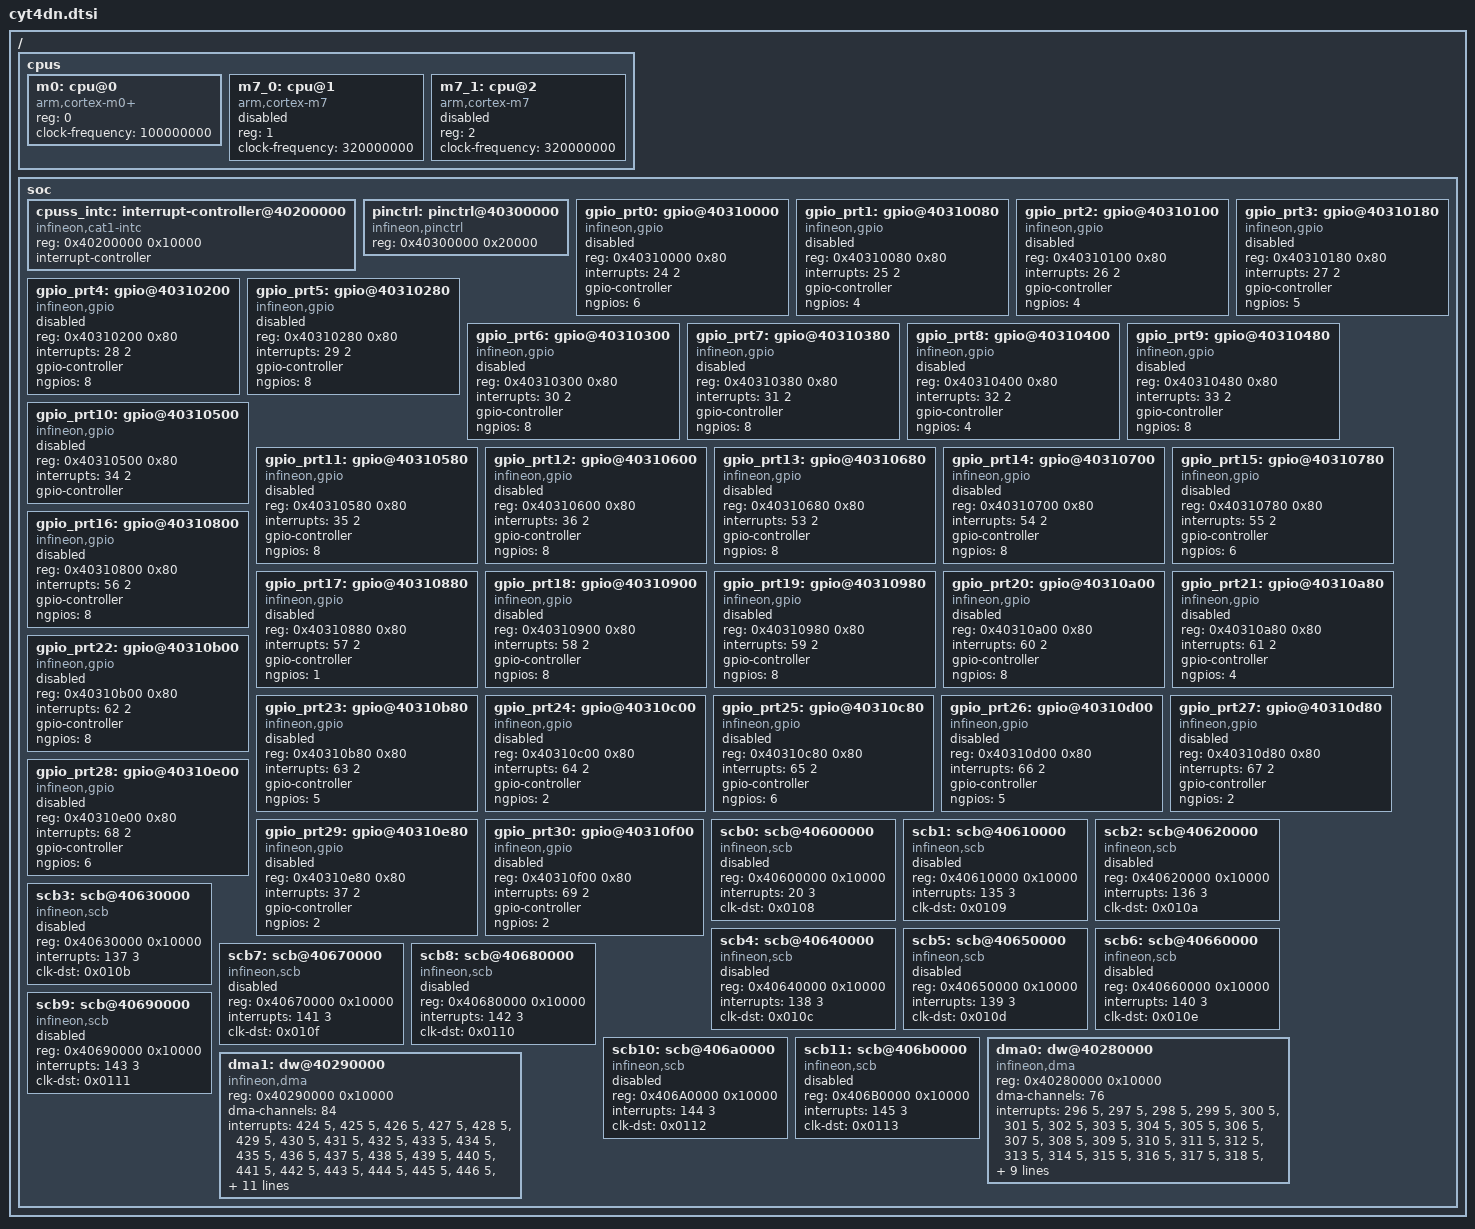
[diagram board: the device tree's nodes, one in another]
/*
 * Copyright (c) 2026 Linumiz
 * Copyright (c) 2026 Infineon Technologies AG
 *
 * SPDX-License-Identifier: Apache-2.0
 */

#include <mem.h>
#include <zephyr/dt-bindings/pinctrl/ifx_cat1-pinctrl.h>
#include <zephyr/dt-bindings/memory-attr/memory-attr-arm.h>

/ {
	cpus {
		#address-cells = <1>;
		#size-cells = <0>;

		m0: cpu@0 {
			device_type = "cpu";
			compatible = "arm,cortex-m0+";
			reg = <0>;
			clock-frequency = <100000000>;
		};

		m7_0: cpu@1 {
			device_type = "cpu";
			compatible = "arm,cortex-m7";
			reg = <1>;
			clock-frequency = <320000000>;
			status = "disabled";
		};

		m7_1: cpu@2 {
			device_type = "cpu";
			compatible = "arm,cortex-m7";
			reg = <2>;
			clock-frequency = <320000000>;
			status = "disabled";
		};
	};

	soc {
		cpuss_intc: interrupt-controller@40200000 {
			compatible = "infineon,cat1-intc";
			reg = <0x40200000 0x10000>;
			#interrupt-cells = <2>;
			interrupt-controller;
			status = "okay";
		};

		pinctrl: pinctrl@40300000 {
			compatible = "infineon,pinctrl";
			reg = <0x40300000 0x20000>;
		};

		gpio_prt0: gpio@40310000 {
			compatible = "infineon,gpio";
			reg = <0x40310000 0x80>;
			interrupts = <24 2>;
			gpio-controller;
			ngpios = <6>;
			status = "disabled";
			#gpio-cells = <2>;
		};

		gpio_prt1: gpio@40310080 {
			compatible = "infineon,gpio";
			reg = <0x40310080 0x80>;
			interrupts = <25 2>;
			gpio-controller;
			ngpios = <4>;
			status = "disabled";
			#gpio-cells = <2>;
		};

		gpio_prt2: gpio@40310100 {
			compatible = "infineon,gpio";
			reg = <0x40310100 0x80>;
			interrupts = <26 2>;
			gpio-controller;
			ngpios = <4>;
			status = "disabled";
			#gpio-cells = <2>;
		};

		gpio_prt3: gpio@40310180 {
			compatible = "infineon,gpio";
			reg = <0x40310180 0x80>;
			interrupts = <27 2>;
			gpio-controller;
			ngpios = <5>;
			status = "disabled";
			#gpio-cells = <2>;
		};

		gpio_prt4: gpio@40310200 {
			compatible = "infineon,gpio";
			reg = <0x40310200 0x80>;
			interrupts = <28 2>;
			gpio-controller;
			ngpios = <8>;
			status = "disabled";
			#gpio-cells = <2>;
		};

		gpio_prt5: gpio@40310280 {
			compatible = "infineon,gpio";
			reg = <0x40310280 0x80>;
			interrupts = <29 2>;
			gpio-controller;
			ngpios = <8>;
			status = "disabled";
			#gpio-cells = <2>;
		};

		gpio_prt6: gpio@40310300 {
			compatible = "infineon,gpio";
			reg = <0x40310300 0x80>;
			interrupts = <30 2>;
			gpio-controller;
			ngpios = <8>;
			status = "disabled";
			#gpio-cells = <2>;
		};

		gpio_prt7: gpio@40310380 {
			compatible = "infineon,gpio";
			reg = <0x40310380 0x80>;
			interrupts = <31 2>;
			gpio-controller;
			ngpios = <8>;
			status = "disabled";
			#gpio-cells = <2>;
		};

		gpio_prt8: gpio@40310400 {
			compatible = "infineon,gpio";
			reg = <0x40310400 0x80>;
			interrupts = <32 2>;
			gpio-controller;
			ngpios = <4>;
			status = "disabled";
			#gpio-cells = <2>;
		};

		gpio_prt9: gpio@40310480 {
			compatible = "infineon,gpio";
			reg = <0x40310480 0x80>;
			interrupts = <33 2>;
			gpio-controller;
			ngpios = <8>;
			status = "disabled";
			#gpio-cells = <2>;
		};

		gpio_prt10: gpio@40310500 {
			compatible = "infineon,gpio";
			reg = <0x40310500 0x80>;
			interrupts = <34 2>;
			gpio-controller;
			status = "disabled";
			#gpio-cells = <2>;
		};

		gpio_prt11: gpio@40310580 {
			compatible = "infineon,gpio";
			reg = <0x40310580 0x80>;
			interrupts = <35 2>;
			gpio-controller;
			ngpios = <8>;
			status = "disabled";
			#gpio-cells = <2>;
		};

		gpio_prt12: gpio@40310600 {
			compatible = "infineon,gpio";
			reg = <0x40310600 0x80>;
			interrupts = <36 2>;
			gpio-controller;
			ngpios = <8>;
			status = "disabled";
			#gpio-cells = <2>;
		};

		gpio_prt13: gpio@40310680 {
			compatible = "infineon,gpio";
			reg = <0x40310680 0x80>;
			interrupts = <53 2>;
			gpio-controller;
			ngpios = <8>;
			status = "disabled";
			#gpio-cells = <2>;
		};

		gpio_prt14: gpio@40310700 {
			compatible = "infineon,gpio";
			reg = <0x40310700 0x80>;
			interrupts = <54 2>;
			gpio-controller;
			ngpios = <8>;
			status = "disabled";
			#gpio-cells = <2>;
		};

		gpio_prt15: gpio@40310780 {
			compatible = "infineon,gpio";
			reg = <0x40310780 0x80>;
			interrupts = <55 2>;
			gpio-controller;
			ngpios = <6>;
			status = "disabled";
			#gpio-cells = <2>;
		};

		gpio_prt16: gpio@40310800 {
			compatible = "infineon,gpio";
			reg = <0x40310800 0x80>;
			interrupts = <56 2>;
			gpio-controller;
			ngpios = <8>;
			status = "disabled";
			#gpio-cells = <2>;
		};

		gpio_prt17: gpio@40310880 {
			compatible = "infineon,gpio";
			reg = <0x40310880 0x80>;
			interrupts = <57 2>;
			gpio-controller;
			ngpios = <1>;
			status = "disabled";
			#gpio-cells = <2>;
		};

		gpio_prt18: gpio@40310900 {
			compatible = "infineon,gpio";
			reg = <0x40310900 0x80>;
			interrupts = <58 2>;
			gpio-controller;
			ngpios = <8>;
			status = "disabled";
			#gpio-cells = <2>;
		};

		gpio_prt19: gpio@40310980 {
			compatible = "infineon,gpio";
			reg = <0x40310980 0x80>;
			interrupts = <59 2>;
			gpio-controller;
			ngpios = <8>;
			status = "disabled";
			#gpio-cells = <2>;
		};

		gpio_prt20: gpio@40310a00 {
			compatible = "infineon,gpio";
			reg = <0x40310a00 0x80>;
			interrupts = <60 2>;
			gpio-controller;
			ngpios = <8>;
			status = "disabled";
			#gpio-cells = <2>;
		};

		gpio_prt21: gpio@40310a80 {
			compatible = "infineon,gpio";
			reg = <0x40310a80 0x80>;
			interrupts = <61 2>;
			gpio-controller;
			ngpios = <4>;
			status = "disabled";
			#gpio-cells = <2>;
		};

		gpio_prt22: gpio@40310b00 {
			compatible = "infineon,gpio";
			reg = <0x40310b00 0x80>;
			interrupts = <62 2>;
			gpio-controller;
			ngpios = <8>;
			status = "disabled";
			#gpio-cells = <2>;
		};

		gpio_prt23: gpio@40310b80 {
			compatible = "infineon,gpio";
			reg = <0x40310b80 0x80>;
			interrupts = <63 2>;
			gpio-controller;
			ngpios = <5>;
			status = "disabled";
			#gpio-cells = <2>;
		};

		gpio_prt24: gpio@40310c00 {
			compatible = "infineon,gpio";
			reg = <0x40310c00 0x80>;
			interrupts = <64 2>;
			gpio-controller;
			ngpios = <2>;
			status = "disabled";
			#gpio-cells = <2>;
		};

		gpio_prt25: gpio@40310c80 {
			compatible = "infineon,gpio";
			reg = <0x40310c80 0x80>;
			interrupts = <65 2>;
			gpio-controller;
			ngpios = <6>;
			status = "disabled";
			#gpio-cells = <2>;
		};

		gpio_prt26: gpio@40310d00 {
			compatible = "infineon,gpio";
			reg = <0x40310d00 0x80>;
			interrupts = <66 2>;
			gpio-controller;
			ngpios = <5>;
			status = "disabled";
			#gpio-cells = <2>;
		};

		gpio_prt27: gpio@40310d80 {
			compatible = "infineon,gpio";
			reg = <0x40310d80 0x80>;
			interrupts = <67 2>;
			gpio-controller;
			ngpios = <2>;
			status = "disabled";
			#gpio-cells = <2>;
		};

		gpio_prt28: gpio@40310e00 {
			compatible = "infineon,gpio";
			reg = <0x40310e00 0x80>;
			interrupts = <68 2>;
			gpio-controller;
			ngpios = <6>;
			status = "disabled";
			#gpio-cells = <2>;
		};

		gpio_prt29: gpio@40310e80 {
			compatible = "infineon,gpio";
			reg = <0x40310e80 0x80>;
			interrupts = <37 2>;
			gpio-controller;
			ngpios = <2>;
			status = "disabled";
			#gpio-cells = <2>;
		};

		gpio_prt30: gpio@40310f00 {
			compatible = "infineon,gpio";
			reg = <0x40310f00 0x80>;
			interrupts = <69 2>;
			gpio-controller;
			ngpios = <2>;
			status = "disabled";
			#gpio-cells = <2>;
		};

		scb0: scb@40600000 {
                        compatible = "infineon,scb";
                        reg = <0x40600000 0x10000>;
                        interrupts = <20 3>;
			clk-dst = <0x0108>;
                        status = "disabled";
                };

		scb1: scb@40610000 {
			compatible = "infineon,scb";
			reg = <0x40610000 0x10000>;
			interrupts = <135 3>;
			clk-dst = <0x0109>;
			status = "disabled";
		};

		scb2: scb@40620000 {
			compatible = "infineon,scb";
			reg = <0x40620000 0x10000>;
			interrupts = <136 3>;
			clk-dst = <0x010a>;
			status = "disabled";
		};

		scb3: scb@40630000 {
			compatible = "infineon,scb";
			reg = <0x40630000 0x10000>;
			interrupts = <137 3>;
			clk-dst = <0x010b>;
			status = "disabled";
		};

		scb4: scb@40640000 {
			compatible = "infineon,scb";
			reg = <0x40640000 0x10000>;
			interrupts = <138 3>;
			clk-dst = <0x010c>;
			status = "disabled";
		};

		scb5: scb@40650000 {
			compatible = "infineon,scb";
			reg = <0x40650000 0x10000>;
			interrupts = <139 3>;
			clk-dst = <0x010d>;
			status = "disabled";
		};

		scb6: scb@40660000 {
			compatible = "infineon,scb";
			reg = <0x40660000 0x10000>;
			interrupts = <140 3>;
			clk-dst = <0x010e>;
			status = "disabled";
		};

		scb7: scb@40670000 {
			compatible = "infineon,scb";
			reg = <0x40670000 0x10000>;
			interrupts = <141 3>;
			clk-dst = <0x010f>;
			status = "disabled";
		};

		scb8: scb@40680000 {
			compatible = "infineon,scb";
			reg = <0x40680000 0x10000>;
			interrupts = <142 3>;
			clk-dst = <0x0110>;
			status = "disabled";
		};

		scb9: scb@40690000 {
			compatible = "infineon,scb";
			reg = <0x40690000 0x10000>;
			interrupts = <143 3>;
			clk-dst = <0x0111>;
			status = "disabled";
		};

		scb10: scb@406a0000 {
			compatible = "infineon,scb";
			reg = <0x406A0000 0x10000>;
			interrupts = <144 3>;
			clk-dst = <0x0112>;
			status = "disabled";
		};

		scb11: scb@406b0000 {
			compatible = "infineon,scb";
			reg = <0x406B0000 0x10000>;
			interrupts = <145 3>;
			clk-dst = <0x0113>;
			status = "disabled";
		};

		dma0: dw@40280000 {
			#dma-cells = <1>;
			compatible = "infineon,dma";
			reg = <0x40280000 0x10000>;
			dma-channels = <76>;
			interrupts = <296 5>, /* CH0 */
				     <297 5>, /* CH1 */
				     <298 5>, /* CH2 */
				     <299 5>, /* CH3 */
				     <300 5>, /* CH4 */
				     <301 5>, /* CH5 */
				     <302 5>, /* CH6 */
				     <303 5>, /* CH7 */
				     <304 5>, /* CH8 */
				     <305 5>, /* CH9 */
				     <306 5>, /* CH10 */
				     <307 5>, /* CH11 */
				     <308 5>, /* CH12 */
				     <309 5>, /* CH13 */
				     <310 5>, /* CH14 */
				     <311 5>, /* CH15 */
				     <312 5>, /* CH16 */
				     <313 5>, /* CH17 */
				     <314 5>, /* CH18 */
				     <315 5>, /* CH19 */
				     <316 5>, /* CH20 */
				     <317 5>, /* CH21 */
				     <318 5>, /* CH22 */
				     <319 5>, /* CH23 */
				     <320 5>, /* CH24 */
				     <321 5>, /* CH25 */
				     <322 5>, /* CH26 */
				     <323 5>, /* CH27 */
				     <324 5>, /* CH28 */
				     <325 5>, /* CH29 */
				     <326 5>, /* CH30 */
				     <327 5>, /* CH31 */
				     <328 5>, /* CH32 */
				     <329 5>, /* CH33 */
				     <330 5>, /* CH34 */
				     <331 5>, /* CH35 */
				     <332 5>, /* CH36 */
				     <333 5>, /* CH37 */
				     <334 5>, /* CH38 */
				     <335 5>, /* CH39 */
				     <336 5>, /* CH40 */
				     <337 5>, /* CH41 */
				     <338 5>, /* CH42 */
				     <339 5>, /* CH43 */
				     <340 5>, /* CH44 */
				     <341 5>, /* CH45 */
				     <342 5>, /* CH46 */
				     <343 5>, /* CH47 */
				     <344 5>, /* CH48 */
				     <345 5>, /* CH49 */
				     <346 5>, /* CH50 */
				     <347 5>, /* CH51 */
				     <348 5>, /* CH52 */
				     <349 5>, /* CH53 */
				     <350 5>, /* CH54 */
				     <351 5>, /* CH55 */
				     <352 5>, /* CH56 */
				     <353 5>, /* CH57 */
				     <354 5>, /* CH58 */
				     <355 5>, /* CH59 */
				     <356 5>, /* CH60 */
				     <357 5>, /* CH61 */
				     <358 5>, /* CH62 */
				     <359 5>, /* CH63 */
				     <360 5>, /* CH64 */
				     <361 5>, /* CH65 */
				     <362 5>, /* CH66 */
				     <363 5>, /* CH67 */
				     <364 5>, /* CH68 */
				     <365 5>, /* CH69 */
				     <366 5>, /* CH70 */
				     <367 5>, /* CH71 */
				     <368 5>, /* CH72 */
				     <369 5>, /* CH73 */
				     <370 5>, /* CH74 */
				     <371 5>; /* CH75 */
			status = "okay";
		};

		dma1: dw@40290000 {
			#dma-cells = <1>;
			compatible = "infineon,dma";
			reg = <0x40290000 0x10000>;
			dma-channels = <84>;
			interrupts = <424 5>, /* CH0 */
				     <425 5>, /* CH1 */
				     <426 5>, /* CH2 */
				     <427 5>, /* CH3 */
				     <428 5>, /* CH4 */
				     <429 5>, /* CH5 */
				     <430 5>, /* CH6 */
				     <431 5>, /* CH7 */
				     <432 5>, /* CH8 */
				     <433 5>, /* CH9 */
				     <434 5>, /* CH10 */
				     <435 5>, /* CH11 */
				     <436 5>, /* CH12 */
				     <437 5>, /* CH13 */
				     <438 5>, /* CH14 */
				     <439 5>, /* CH15 */
				     <440 5>, /* CH16 */
				     <441 5>, /* CH17 */
				     <442 5>, /* CH18 */
				     <443 5>, /* CH19 */
				     <444 5>, /* CH20 */
				     <445 5>, /* CH21 */
				     <446 5>, /* CH22 */
				     <447 5>, /* CH23 */
				     <448 5>, /* CH24 */
				     <449 5>, /* CH25 */
				     <450 5>, /* CH26 */
				     <451 5>, /* CH27 */
				     <452 5>, /* CH28 */
				     <453 5>, /* CH29 */
				     <454 5>, /* CH30 */
				     <455 5>, /* CH31 */
				     <456 5>, /* CH32 */
				     <457 5>, /* CH33 */
				     <458 5>, /* CH34 */
				     <459 5>, /* CH35 */
				     <460 5>, /* CH36 */
				     <461 5>, /* CH37 */
				     <462 5>, /* CH38 */
				     <463 5>, /* CH39 */
				     <464 5>, /* CH40 */
				     <465 5>, /* CH41 */
				     <466 5>, /* CH42 */
				     <467 5>, /* CH43 */
				     <468 5>, /* CH44 */
				     <469 5>, /* CH45 */
				     <470 5>, /* CH46 */
				     <471 5>, /* CH47 */
				     <472 5>, /* CH48 */
				     <473 5>, /* CH49 */
				     <474 5>, /* CH50 */
				     <475 5>, /* CH51 */
				     <476 5>, /* CH52 */
				     <477 5>, /* CH53 */
				     <478 5>, /* CH54 */
				     <479 5>, /* CH55 */
				     <480 5>, /* CH56 */
				     <481 5>, /* CH57 */
				     <482 5>, /* CH58 */
				     <483 5>, /* CH59 */
				     <484 5>, /* CH60 */
				     <485 5>, /* CH61 */
				     <486 5>, /* CH62 */
				     <487 5>, /* CH63 */
				     <488 5>, /* CH64 */
				     <489 5>, /* CH65 */
				     <490 5>, /* CH66 */
				     <491 5>, /* CH67 */
				     <492 5>, /* CH68 */
				     <493 5>, /* CH69 */
				     <494 5>, /* CH70 */
				     <495 5>, /* CH71 */
				     <496 5>, /* CH72 */
				     <497 5>, /* CH73 */
				     <498 5>, /* CH74 */
				     <499 5>, /* CH75 */
				     <500 5>, /* CH76 */
				     <501 5>, /* CH77 */
				     <502 5>, /* CH78 */
				     <503 5>, /* CH79 */
				     <504 5>, /* CH80 */
				     <505 5>, /* CH81 */
				     <506 5>, /* CH82 */
				     <507 5>; /* CH83 */
			status = "okay";
		};
	};
};
